# PIC32CM5112SG00100 register map
Vendor: Microchip Technology; Series: PIC32CMSG00; File version: 0
CPU: CM23 r0p0, little endian, MPU, no FPU, 2 interrupt priority bits, 141 interrupts, 13 SAU regions
Registers are 32-bit, read-write, reset 0x0 unless marked. A register's access mark holds for its fields unless they carry their own. Offsets are from the block's base; [hi:lo] are bit positions; {n}, {i} and the like mark numbered series; 'fields as' and 'values as' point back to an identical list.

## MCLK — Polaris Main Clock Controller
Base 0x4400A000
0x00 INTENCLR write-1-clears — Interrupt Enable Clear Register
  [0] CKRDY — Clock Ready Interrupt Enable Clear
    0=The Clock Ready interrupt is disabled; 1=The Clock Ready interrupt is enabled
0x04 INTENSET write-1-sets — Interrupt Enable Set Register
  [0] CKRDY — Clock Ready Interrupt Enable Set
    values as INTENCLR.CKRDY
0x08 INTFLAG wo reset 0x1 write-1-clears — Interrupt Flag Status Register
  [0] CKRDY — Clock Ready Interrupt Flag
{0xC+4i} CLKDIV[{i}] (i=0..2) — Clock Divider Control n Register
  [7:0] DIV — Clock Domain n Division Factor
    1=Divide by 1; 2=Divide by 2; 4=Divide by 4; 8=Divide by 8; 16=Divide by 16; 32=Divide by 32; 64=Divide by 64; 128=Divide by 128
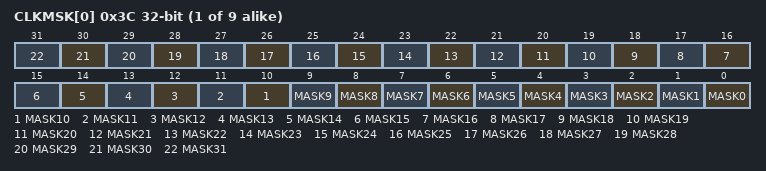
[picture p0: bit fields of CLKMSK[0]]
{0x3C+4i} CLKMSK[{i}] (i=0..8) — Peripheral Clock Enable Mask n Register
  [all] fields
    0=Peripheral clock mclk_clk_periph[n*32+x] stopped; 1=Peripheral clock mclk_clk_periph[n*32+x] enabled
  [n] MASK{n} (n=0..31) — Peripheral Clock Enable Mask

## MCRAMC — Multi-Channel RAM Controller
Base 0x4402C000
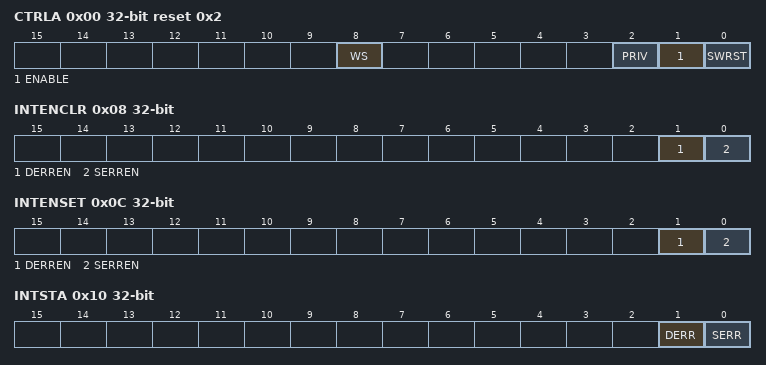
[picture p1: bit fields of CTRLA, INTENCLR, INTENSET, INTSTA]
0x00 CTRLA reset 0x2 — Control Enable A Register
  [8] WS — Wait State Enable
  [2] PRIV — Priviledged Access Enable
  [1] ENABLE — ECC Decoder Enable
    0=ECC decoding is disabled; 1=ECC decoding is enabled
  [0] SWRST — Software Reset
    0=No effect; 1=Reset the MCRAMC. A software-triggered hardware reset of the MCRAMC user interface is performed.
0x08 INTENCLR — Interrupt Enable Clear Register
  [1] DERREN — Double Bit Error Interrupt Enable, Clear
  [0] SERREN — Single Bit Error Interrupt Enable, Clear
0x0C INTENSET — Interrupt Enable Set Register
  [1] DERREN — Double Bit Error Interrupt Enable, Set
  [0] SERREN — Single Bit Error Interrupt Enable, Set
0x10 INTSTA — Interrupt Status Register
  [1] DERR — Double Bit Error
  [0] SERR — Single Bit Error
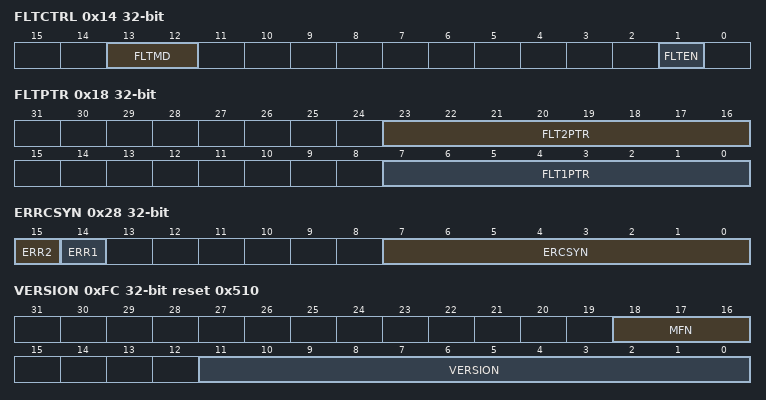
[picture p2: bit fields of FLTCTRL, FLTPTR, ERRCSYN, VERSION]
0x14 FLTCTRL — Fault Injection Control Register
  [13:12] FLTMD — Fault Injection Mode
  [1] FLTEN — Fault Injection Enabled
    0=Disables fault injection; 1=Enables fault injection at FLTADR address offset as selected by FLTMD and FLTxPTR
0x18 FLTPTR — Fault Injection Pointer Register
  [23:16] FLT2PTR — Double Fault Injection Bit Pointer
  [7:0] FLT1PTR — Single Fault Injection Bit Pointer
0x1C FLTADR — Fault Injection Address Register
  [23:0] FLTADR — Fault Address Offset
0x20 ERRCADR ro — Error Capture Address Register
  [23:0] ERCADR — ECC SECDED Error Capture Address
0x24 ERRCPAR ro — Error Capture Parity Register
  [7:0] ERCPAR — ECC SECDED Error Capture Parity
0x28 ERRCSYN ro — Error Capture Syndrome Register
  [15] ERR2 — ECC Double Bit Error
    0=Not a Double bit error; 1=Double bit error
  [14] ERR1 — ECC Single Bit Error
  [7:0] ERCSYN — ECC SECDED Error Capture Syndrome
    0=Not a Single bit error; 1=Single bit error
0xFC VERSION ro reset 0x510
  [18:16] MFN — Metal Fix Number
  [11:0] VERSION — MCRAMC Version

## MPU — Memory Protection Unit
Base 0xE000ED90
Same registers: MPU_NS 0xE002ED90
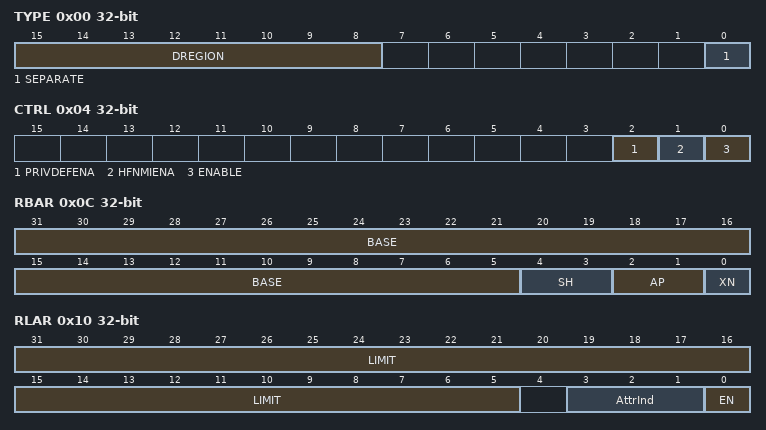
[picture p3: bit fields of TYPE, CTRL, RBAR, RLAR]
0x00 TYPE ro — MPU Type Register
  [15:8] DREGION — Number of MPU data regions
  [0] SEPARATE — Separate instructions and data address regions
0x04 CTRL — MPU Control Register
  [2] PRIVDEFENA — Privileged default enable
  [1] HFNMIENA — HardFault, NMI enable
  [0] ENABLE — MPU enable
0x08 RNR — MPU Region Number Register
  [7:0] REGION — Selected region number
0x0C RBAR — MPU Region Base Address Register
  [31:5] BASE — Base address
  [4:3] SH — Shareability
    0=NO (Non-shareable); 2=OUTER (Outer shareable); 3=INNER (Inner shareable)
  [2:1] AP — Access permissions
    0=RWPRIV (Read/write by privileged code only); 1=RWANY (Read/write by any privilege level); 2=RPRIV (Read-only by privileged code only); 3=RANY (Read-only by any privilege level)
  [0] XN — Execute Never
0x10 RLAR — MPU Region Limit Address Register
  [31:5] LIMIT — Limit address
  [3:1] AttrInd — Attribute Index
  [0] EN — Region enable
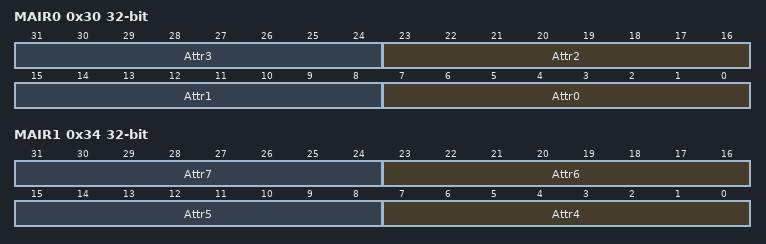
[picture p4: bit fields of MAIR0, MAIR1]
0x30 MAIR0 — MPU Memory Attribute Indirection Register 0
  [8n+7:8n] Attr{n} (n=0..3) — Attribute of MPU region {n}
0x34 MAIR1 — MPU Memory Attribute Indirection Register 1
  [8n-25:8n-32] Attr{n} (n=4..7) — Attribute of MPU region {n}
